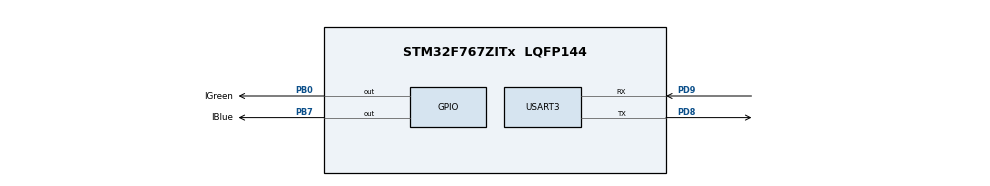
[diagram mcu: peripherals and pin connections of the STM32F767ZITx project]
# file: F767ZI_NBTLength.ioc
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Mcu.Family=STM32F7
TIM6.Prescaler=16-1
VP_TIM6_VS_ClockSourceINT.Mode=Enable_Timer
PB0.GPIO_Label=IGreen
PD9.Signal=USART3_RX
PD9.Mode=Asynchronous
ProjectManager.StackSize=0x400
USART3.VirtualMode-Asynchronous=VM_ASYNC
PA13.Signal=SYS_JTMS-SWDIO
ProjectManager.TargetToolchain=STM32CubeIDE
PD8.Signal=USART3_TX
RCC.USBFreq_Value=96000000
RCC.LSE_VALUE=32768
PD8.Mode=Asynchronous
RCC.HSE_VALUE=25000000
board=custom
RCC.VCOOutputFreq_Value=192000000
PB7.Signal=GPIO_Output
TIM6.Period=65535-1
Mcu.Name=STM32F767ZITx
PB7.GPIO_Label=IBlue
Mcu.Package=LQFP144
PA14.Signal=SYS_JTCK-SWCLK
ProjectManager.HeapSize=0x200
RCC.HSI_VALUE=16000000
NVIC.PriorityGroup=NVIC_PRIORITYGROUP_4
RCC.APB1TimFreq_Value=16000000
RCC.APB1Freq_Value=16000000
PB0.Signal=GPIO_Output

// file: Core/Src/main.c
/* USER CODE BEGIN Header */
/**
  ******************************************************************************
  * @file           : main.c
  * @brief          : Main program body
  ******************************************************************************
  * @attention
  *
  * <h2><center>&copy; Copyright (c) 2022 STMicroelectronics.
  * All rights reserved.</center></h2>
  *
  * This software component is licensed by ST under BSD 3-Clause license,
  * the "License"; You may not use this file except in compliance with the
  * License. You may obtain a copy of the License at:
  *                        opensource.org/licenses/BSD-3-Clause
  *
  ******************************************************************************
  */
/* USER CODE END Header */
#include "main.h"
// 1. For support of sprintf
#include <stdio.h>

TIM_HandleTypeDef htim6;

UART_HandleTypeDef huart3;

void SystemClock_Config(void);
static void MX_GPIO_Init(void);
static void MX_TIM6_Init(void);
static void MX_USART3_UART_Init(void);

int main(void)
{
  /* USER CODE BEGIN 1 */
	// 2. For string buffering
	char buffer[50];
	int  buffer_len;
	uint16_t timer_val;
  /* USER CODE END 1 */

  /* MCU Configuration--------------------------------------------------------*/

  /* Reset of all peripherals, Initializes the Flash interface and the Systick. */
  HAL_Init();

  /* Configure the system clock */
  SystemClock_Config();

  /* Initialize all configured peripherals */
  MX_GPIO_Init();
  MX_TIM6_Init();
  MX_USART3_UART_Init();

  /* USER CODE BEGIN 2 */
  // 3. You must start
  HAL_TIM_Base_Start(&htim6);

  // 4. Prepare a string and send it to UART
  buffer_len = sprintf( buffer, "Measuring time test\r\n");
  HAL_UART_Transmit(&huart3, (uint8_t *) buffer, buffer_len, 100);
  /* USER CODE END 2 */

  /* Infinite loop */
  while (1)
  {
	  // Read the first timestamp (counter register)
	          timer_val = __HAL_TIM_GET_COUNTER(&htim6);

	          // Do some work
	          HAL_Delay(50);

	          // Read the second timestamp and computer the counter difference
	          timer_val = __HAL_TIM_GET_COUNTER(&htim6) - timer_val;

	          // Transform an unsigned int value to a string
	          buffer_len = sprintf(buffer,"%u us\r\n", timer_val);

	          // Send data to UART3
	          HAL_UART_Transmit(&huart3, (uint8_t *) buffer, buffer_len, 100);

	          // Wait half a second before next measurement
	          HAL_Delay(1000);
  }
}

void SystemClock_Config(void)
{
  RCC_OscInitTypeDef RCC_OscInitStruct = {0};
  RCC_ClkInitTypeDef RCC_ClkInitStruct = {0};
  RCC_PeriphCLKInitTypeDef PeriphClkInitStruct = {0};

  /** Configure the main internal regulator output voltage
  */
  __HAL_RCC_PWR_CLK_ENABLE();
  __HAL_PWR_VOLTAGESCALING_CONFIG(PWR_REGULATOR_VOLTAGE_SCALE3);
  /** Initializes the RCC Oscillators according to the specified parameters
  * in the RCC_OscInitTypeDef structure.
  */
  RCC_OscInitStruct.OscillatorType = RCC_OSCILLATORTYPE_HSI;
  RCC_OscInitStruct.HSIState = RCC_HSI_ON;
  RCC_OscInitStruct.HSICalibrationValue = RCC_HSICALIBRATION_DEFAULT;
  RCC_OscInitStruct.PLL.PLLState = RCC_PLL_NONE;
  if (HAL_RCC_OscConfig(&RCC_OscInitStruct) != HAL_OK)
  {
    Error_Handler();
  }
  /** Initializes the CPU, AHB and APB buses clocks
  */
  RCC_ClkInitStruct.ClockType = RCC_CLOCKTYPE_HCLK|RCC_CLOCKTYPE_SYSCLK
                              |RCC_CLOCKTYPE_PCLK1|RCC_CLOCKTYPE_PCLK2;
  RCC_ClkInitStruct.SYSCLKSource = RCC_SYSCLKSOURCE_HSI;
  RCC_ClkInitStruct.AHBCLKDivider = RCC_SYSCLK_DIV1;
  RCC_ClkInitStruct.APB1CLKDivider = RCC_HCLK_DIV1;
  RCC_ClkInitStruct.APB2CLKDivider = RCC_HCLK_DIV1;

  if (HAL_RCC_ClockConfig(&RCC_ClkInitStruct, FLASH_LATENCY_0) != HAL_OK)
  {
    Error_Handler();
  }
  PeriphClkInitStruct.PeriphClockSelection = RCC_PERIPHCLK_USART3;
  PeriphClkInitStruct.Usart3ClockSelection = RCC_USART3CLKSOURCE_PCLK1;
  if (HAL_RCCEx_PeriphCLKConfig(&PeriphClkInitStruct) != HAL_OK)
  {
    Error_Handler();
  }
}

static void MX_TIM6_Init(void)
{

  TIM_MasterConfigTypeDef sMasterConfig = {0};

  htim6.Instance = TIM6;
  htim6.Init.Prescaler = 16-1;
  htim6.Init.CounterMode = TIM_COUNTERMODE_UP;
  htim6.Init.Period = 65535-1;
  htim6.Init.AutoReloadPreload = TIM_AUTORELOAD_PRELOAD_DISABLE;
  if (HAL_TIM_Base_Init(&htim6) != HAL_OK)
  {
    Error_Handler();
  }
  sMasterConfig.MasterOutputTrigger = TIM_TRGO_RESET;
  sMasterConfig.MasterSlaveMode = TIM_MASTERSLAVEMODE_DISABLE;
  if (HAL_TIMEx_MasterConfigSynchronization(&htim6, &sMasterConfig) != HAL_OK)
  {
    Error_Handler();
  }

}

static void MX_USART3_UART_Init(void)
{

  huart3.Instance = USART3;
  huart3.Init.BaudRate = 115200;
  huart3.Init.WordLength = UART_WORDLENGTH_8B;
  huart3.Init.StopBits = UART_STOPBITS_1;
  huart3.Init.Parity = UART_PARITY_NONE;
  huart3.Init.Mode = UART_MODE_TX_RX;
  huart3.Init.HwFlowCtl = UART_HWCONTROL_NONE;
  huart3.Init.OverSampling = UART_OVERSAMPLING_16;
  huart3.Init.OneBitSampling = UART_ONE_BIT_SAMPLE_DISABLE;
  huart3.AdvancedInit.AdvFeatureInit = UART_ADVFEATURE_NO_INIT;
  if (HAL_UART_Init(&huart3) != HAL_OK)
  {
    Error_Handler();
  }

}

static void MX_GPIO_Init(void)
{
  GPIO_InitTypeDef GPIO_InitStruct = {0};

  /* GPIO Ports Clock Enable */
  __HAL_RCC_GPIOB_CLK_ENABLE();
  __HAL_RCC_GPIOD_CLK_ENABLE();
  __HAL_RCC_GPIOA_CLK_ENABLE();

  /*Configure GPIO pin Output Level */
  HAL_GPIO_WritePin(GPIOB, IGreen_Pin|IBlue_Pin, GPIO_PIN_RESET);

  /*Configure GPIO pins : IGreen_Pin IBlue_Pin */
  GPIO_InitStruct.Pin = IGreen_Pin|IBlue_Pin;
  GPIO_InitStruct.Mode = GPIO_MODE_OUTPUT_PP;
  GPIO_InitStruct.Pull = GPIO_NOPULL;
  GPIO_InitStruct.Speed = GPIO_SPEED_FREQ_LOW;
  HAL_GPIO_Init(GPIOB, &GPIO_InitStruct);

}

void Error_Handler(void)
{
  __disable_irq();
  while (1)
  {
  }
}

/************************ (C) COPYRIGHT STMicroelectronics *****END OF FILE****/
